VERSION "ev-fleet bms 1.0"

NS_ :

BS_:

BU_: BMS VCU ThermalMgr MotorFront MotorRear

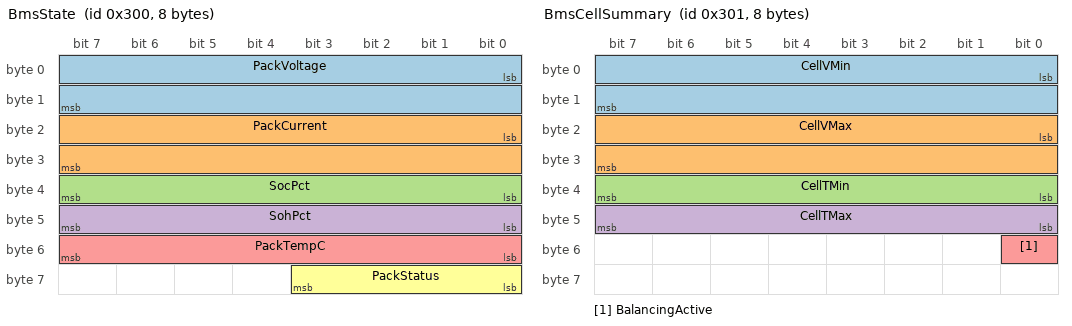
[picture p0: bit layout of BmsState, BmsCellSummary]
BO_ 768 BmsState: 8 BMS
 SG_ PackVoltage : 0|16@1+ (0.1,0) [0|6553.5] "V" VCU,ThermalMgr
 SG_ PackCurrent : 16|16@1- (0.1,0) [-3276.8|3276.7] "A" VCU,ThermalMgr
 SG_ SocPct : 32|8@1+ (0.5,0) [0|127.5] "%" VCU
 SG_ SohPct : 40|8@1+ (0.5,0) [0|127.5] "%" VCU
 SG_ PackTempC : 48|8@1- (1,-40) [-40|87] "degC" VCU,ThermalMgr
 SG_ PackStatus : 56|4@1+ (1,0) [0|15] "" VCU,ThermalMgr

BO_ 769 BmsCellSummary: 8 BMS
 SG_ CellVMin : 0|16@1+ (0.001,0) [0|65.535] "V" VCU
 SG_ CellVMax : 16|16@1+ (0.001,0) [0|65.535] "V" VCU
 SG_ CellTMin : 32|8@1- (1,-40) [-40|87] "degC" VCU,ThermalMgr
 SG_ CellTMax : 40|8@1- (1,-40) [-40|87] "degC" VCU,ThermalMgr
 SG_ BalancingActive : 48|1@1+ (1,0) [0|1] "" VCU

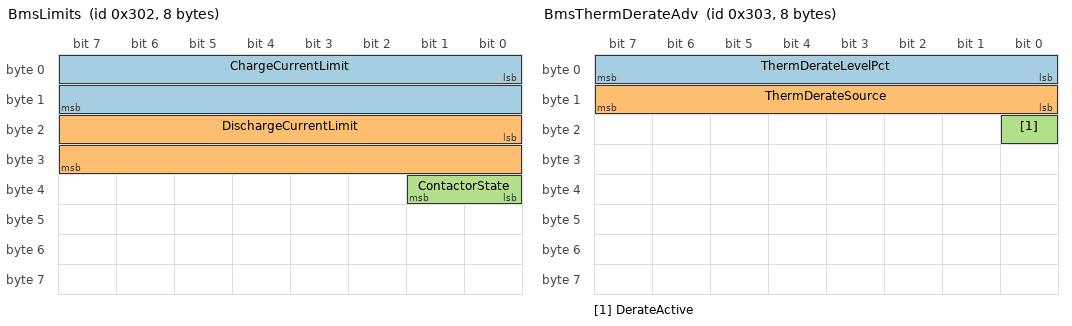
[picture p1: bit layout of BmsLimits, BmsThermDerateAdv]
BO_ 770 BmsLimits: 8 BMS
 SG_ ChargeCurrentLimit : 0|16@1+ (0.1,0) [0|6553.5] "A" VCU,MotorFront,MotorRear
 SG_ DischargeCurrentLimit : 16|16@1+ (0.1,0) [0|6553.5] "A" VCU,MotorFront,MotorRear
 SG_ ContactorState : 32|2@1+ (1,0) [0|3] "" VCU

BO_ 771 BmsThermDerateAdv: 8 BMS
 SG_ ThermDerateLevelPct : 0|8@1+ (0.5,0) [0|127.5] "%" VCU,ThermalMgr
 SG_ ThermDerateSource : 8|8@1+ (1,0) [0|255] "" VCU,ThermalMgr
 SG_ DerateActive : 16|1@1+ (1,0) [0|1] "" VCU

BO_ 772 BmsServiceEvent: 8 BMS
 SG_ EventType M : 0|8@1+ (1,0) [0|3] "" VCU
 SG_ SequenceCounter : 8|8@1+ (1,0) [0|255] "" VCU
 SG_ BootInitStage m1 : 16|8@1+ (1,0) [0|255] "" VCU
 SG_ NvmFailureCode m2 : 16|16@1+ (1,0) [0|65535] "" VCU
 SG_ CellVoltageIndex m3 : 16|8@1+ (1,0) [0|255] "" VCU
 SG_ CellVoltageValue m3 : 24|16@1+ (0.001,0) [0|65.535] "V" VCU

BO_ 773 BmsCellVoltages: 8 BMS
 SG_ CellIndex M : 0|8@1+ (1,0) [0|7] "" VCU
 SG_ Cell01Voltage m0 : 8|16@1+ (0.001,0) [0|65.535] "V" VCU
 SG_ Cell02Voltage m1 : 8|16@1+ (0.001,0) [0|65.535] "V" VCU
 SG_ Cell03Voltage m2 : 8|16@1+ (0.001,0) [0|65.535] "V" VCU
 SG_ Cell04Voltage m3 : 8|16@1+ (0.001,0) [0|65.535] "V" VCU
 SG_ Cell05Voltage m4 : 8|16@1+ (0.001,0) [0|65.535] "V" VCU
 SG_ Cell06Voltage m5 : 8|16@1+ (0.001,0) [0|65.535] "V" VCU
 SG_ Cell07Voltage m6 : 8|16@1+ (0.001,0) [0|65.535] "V" VCU
 SG_ Cell08Voltage m7 : 8|16@1+ (0.001,0) [0|65.535] "V" VCU

CM_ BO_ 768 "Battery pack state, 20 ms cadence on the battery bus, standard 11-bit ID. Read by the VCU (across the bridge) and the thermal manager.";
CM_ BO_ 769 "Cell voltage/temperature extremes, 100 ms cadence.";
CM_ BO_ 770 "Charge/discharge current limits, 100 ms cadence. The inverters clamp torque to the discharge limit.";
CM_ SG_ 770 ContactorState "0=Open 1=Precharge 2=Closed 3=Fault.";
CM_ BO_ 771 "Thermal derate advisory, 200 ms cadence. Uses the DBC long-name extension: the BO_/SG_ lines carry truncated identifiers and the System...LongSymbol attributes below carry the real names.";
CM_ BO_ 772 "Multiplexed service/diagnostic event, 100 ms cadence. EventType selects which arm's payload the frame carries.";
CM_ SG_ 772 EventType "Multiplex selector -- names each event via its value table.";
CM_ BO_ 773 "Indexed cell-voltage series, 100 ms cadence: one self-named signal per CellIndex value. The index-style mux shape -- the selector is an array index, not an enum, so it carries no VAL_ table.";
CM_ SG_ 773 CellIndex "Multiplex selector -- which cell this frame carries.";

BA_DEF_ BO_ "GenMsgCycleTime" INT 0 100000;
BA_DEF_ BO_ "SystemMessageLongSymbol" STRING ;
BA_DEF_ SG_ "SystemSignalLongSymbol" STRING ;
BA_DEF_DEF_ "GenMsgCycleTime" 0;
BA_DEF_DEF_ "SystemMessageLongSymbol" "";
BA_DEF_DEF_ "SystemSignalLongSymbol" "";
BA_ "GenMsgCycleTime" BO_ 768 20;
BA_ "GenMsgCycleTime" BO_ 769 100;
BA_ "GenMsgCycleTime" BO_ 770 100;
BA_ "GenMsgCycleTime" BO_ 771 200;
BA_ "GenMsgCycleTime" BO_ 772 100;
BA_ "GenMsgCycleTime" BO_ 773 100;
BA_ "SystemMessageLongSymbol" BO_ 771 "BatteryManagementSystemThermalDerateAdvisory";
BA_ "SystemSignalLongSymbol" SG_ 771 ThermDerateLevelPct "BatteryPackThermalDerateRequestLevelPercent";
BA_ "SystemSignalLongSymbol" SG_ 771 ThermDerateSource "BatteryPackThermalDerateRequestingSubsystem";

VAL_ 768 PackStatus 0 "Init" 1 "Idle" 2 "Drive" 3 "Charge" 4 "Fault";
VAL_ 770 ContactorState 0 "Open" 1 "Precharge" 2 "Closed" 3 "Fault";
VAL_ 771 ThermDerateSource 0 "NoDerateRequestedNominalThermalEnvelope" 1 "CellTemperatureUpperLimitApproaching" 2 "CoolantInletTemperatureAboveThreshold" 3 "ChargerThermalLimitRequestedByObc" 4 "Fault";
VAL_ 771 DerateActive 0 "Off" 1 "On";
VAL_ 772 EventType 1 "BootInit" 2 "NVMemory" 3 "CellVoltageStatus";
